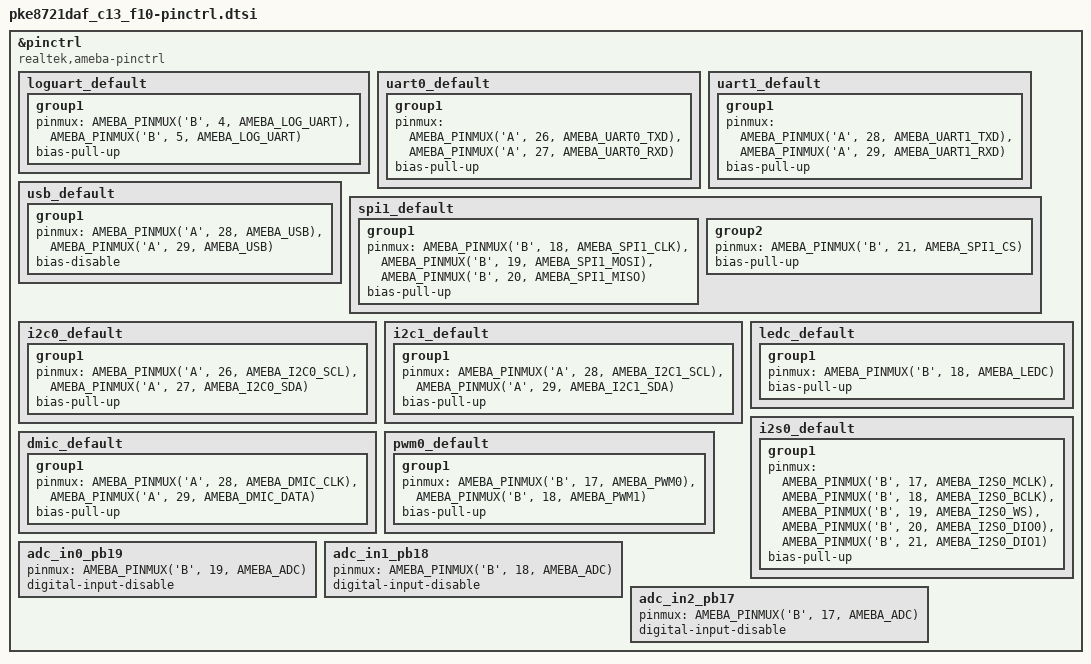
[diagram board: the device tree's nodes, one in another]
/*
 * Copyright (c) 2026 Realtek Semiconductor Corp.
 *
 * SPDX-License-Identifier: Apache-2.0
 */

#include <zephyr/dt-bindings/pinctrl/amebadplus-pinctrl.h>

/*
 * PKE8721DAF-C13-F10 routes 19 module I/O (board spec v1.4 "6 Pin Definition").
 * RTL8721Dx pinmux is a full crossbar: every I/O can be muxed to
 * UART/SPI/I2C/I2S/PWM/LEDC/DMIC/IR/KEY (see PKM8721DAF_pin_mux_v1.0.xlsx),
 * so each peripheral below is mapped onto the flexible routed pins.
 *
 * Locked pins (do NOT reuse):
 *   PB4/PB5              - LOG UART console
 *   PA30/PA31            - SWD debug (also the ROM default UART)
 *   PA13/14/15/16/17/18  - SPIC MCM flash bus (live at runtime)
 *
 * Flexible routed pins, shared by the groups below:
 *   PA26 PA27 PA28 PA29 PB17 PB18 PB19 PB20 PB21
 * These are only 9 pins, so the groups deliberately overlap. Only enable
 * peripherals whose pins do not clash at runtime (e.g. UART0 vs I2C0 both
 * claim PA26/PA27).
 */

&pinctrl {
	compatible = "realtek,ameba-pinctrl";

	loguart_default: loguart_default {
		group1 {
			pinmux = <AMEBA_PINMUX('B', 4, AMEBA_LOG_UART)>,        /* RXD */
				 <AMEBA_PINMUX('B', 5, AMEBA_LOG_UART)>;        /* TXD */
			bias-pull-up;
		};
	};

	uart0_default: uart0_default {
		group1 {
			pinmux = <AMEBA_PINMUX('A', 26, AMEBA_UART0_TXD)>,
				 <AMEBA_PINMUX('A', 27, AMEBA_UART0_RXD)>;
			bias-pull-up;
		};
	};

	uart1_default: uart1_default {
		group1 {
			pinmux = <AMEBA_PINMUX('A', 28, AMEBA_UART1_TXD)>,
				 <AMEBA_PINMUX('A', 29, AMEBA_UART1_RXD)>;
			bias-pull-up;
		};
	};

	usb_default: usb_default {
		group1 {
			pinmux = <AMEBA_PINMUX('A', 28, AMEBA_USB)>,    /* DM */
				 <AMEBA_PINMUX('A', 29, AMEBA_USB)>;    /* DP */
			bias-disable;
		};
	};

	spi1_default: spi1_default {
		group1 {
			pinmux = <AMEBA_PINMUX('B', 18, AMEBA_SPI1_CLK)>,
				 <AMEBA_PINMUX('B', 19, AMEBA_SPI1_MOSI)>,
				 <AMEBA_PINMUX('B', 20, AMEBA_SPI1_MISO)>;
			bias-pull-up;
		};

		group2 {
			pinmux = <AMEBA_PINMUX('B', 21, AMEBA_SPI1_CS)>;
			bias-pull-up;
		};
	};

	/* I2C0: shares PA26/PA27 with UART0 */
	i2c0_default: i2c0_default {
		group1 {
			pinmux = <AMEBA_PINMUX('A', 26, AMEBA_I2C0_SCL)>,
				 <AMEBA_PINMUX('A', 27, AMEBA_I2C0_SDA)>;
			bias-pull-up;
		};
	};

	/* I2C1: shares PA28/PA29 with UART1/USB */
	i2c1_default: i2c1_default {
		group1 {
			pinmux = <AMEBA_PINMUX('A', 28, AMEBA_I2C1_SCL)>,
				 <AMEBA_PINMUX('A', 29, AMEBA_I2C1_SDA)>;
			bias-pull-up;
		};
	};

	ledc_default: ledc_default {
		group1 {
			pinmux = <AMEBA_PINMUX('B', 18, AMEBA_LEDC)>;
			bias-pull-up;
		};
	};

	/* I2S0 full-duplex: shares PB17~PB21 with SPI1/ADC */
	i2s0_default: i2s0_default {
		group1 {
			pinmux = <AMEBA_PINMUX('B', 17, AMEBA_I2S0_MCLK)>,
				 <AMEBA_PINMUX('B', 18, AMEBA_I2S0_BCLK)>,
				 <AMEBA_PINMUX('B', 19, AMEBA_I2S0_WS)>,
				 <AMEBA_PINMUX('B', 20, AMEBA_I2S0_DIO0)>,   /* TX */
				 <AMEBA_PINMUX('B', 21, AMEBA_I2S0_DIO1)>;   /* RX */
			bias-pull-up;
		};
	};

	/* Digital mic: shares PA28/PA29 with I2C1/UART1 */
	dmic_default: dmic_default {
		group1 {
			pinmux = <AMEBA_PINMUX('A', 28, AMEBA_DMIC_CLK)>,
				 <AMEBA_PINMUX('A', 29, AMEBA_DMIC_DATA)>;
			bias-pull-up;
		};
	};

	/* PWM0/PWM1: share PB17/PB18 with I2S0/LEDC/ADC */
	pwm0_default: pwm0_default {
		group1 {
			pinmux = <AMEBA_PINMUX('B', 17, AMEBA_PWM0)>,
				 <AMEBA_PINMUX('B', 18, AMEBA_PWM1)>;
			bias-pull-up;
		};
	};

	/*
	 * ADC channels routed on this board map to the cap-touch pins.
	 * NOTE: PB17~PB19 CANNOT be selected by ADC and CTC simultaneously!!!
	 */
	/omit-if-no-ref/ adc_in0_pb19: adc_in0_pb19 {
		pinmux = <AMEBA_PINMUX('B', 19, AMEBA_ADC)>;   /* TOUCH0_ADC0 */
		digital-input-disable;
	};

	/omit-if-no-ref/ adc_in1_pb18: adc_in1_pb18 {
		pinmux = <AMEBA_PINMUX('B', 18, AMEBA_ADC)>;   /* TOUCH1_ADC1 */
		digital-input-disable;
	};

	/omit-if-no-ref/ adc_in2_pb17: adc_in2_pb17 {
		pinmux = <AMEBA_PINMUX('B', 17, AMEBA_ADC)>;   /* TOUCH2_ADC2 */
		digital-input-disable;
	};
};
